# KEYSTORECTL_1.0 register map
Vendor: Texas Instruments
Peripheral module from a debugger description file (folder mspm33c321x).
Registers are 32-bit, read-write, no defined reset value unless marked. A register's access mark holds for its fields unless they carry their own. Offsets are as the file gives them; lines under a group give offsets from that group; [hi:lo] are bit positions; {n}, {i} and the like mark numbered series; 'fields as' and 'values as' point back to an identical list; <NAME> marks a mode.

## KEYSTORECTL
0x1100 KEYSTORECTL_CFG — Keystore configuration
  [3:0] NK256 — Number of 256 bit keys to be held in the key-store. Can not exceed the total number of slots present in the hardware / 2. For eg: if SYS_N_SLOTS = 4, then atmost 2 256-bit keys can be held in the key-store. Incorrect setting of this field will be reported via STATUS register
    0=ZERO (No 256-bit keys); 1=ONE (One 256-bit key); 2=TWO (Two 256-bit keys); 3=THREE (Three 256-bit keys); 4=FOUR (Four 256-bit keys)
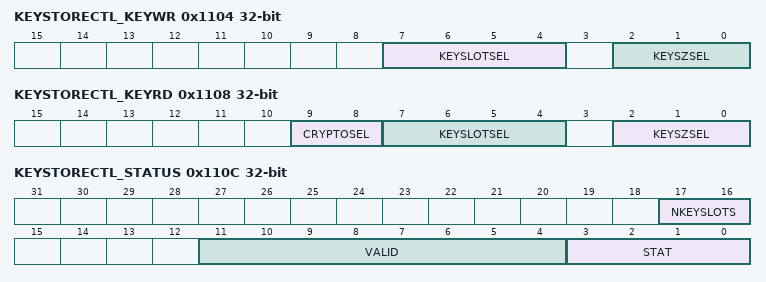
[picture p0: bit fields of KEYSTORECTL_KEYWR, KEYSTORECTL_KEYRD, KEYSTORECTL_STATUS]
0x1104 KEYSTORECTL_KEYWR — Key write configuration
  [7:4] KEYSLOTSEL — Select the key slot to write the key into. NOTE: SW needs to ensure that it is writing to the correct slots. The slot numbering is from 0 through SYS_N_SLOTS-1. Each slot is a 128-bit slot. Therefore, when writing a 256-bit key, two slots will need to budgeted. The selected slot for the 256-bit key needs to be an even numbered slot (eg: 0 or 2). Also all the 256-bit keys need to be stored in lower numbered slots and 128-bit keys stored in higher numbered slots.
    {v}=SLOT{v} (v=0..7)
  [2:0] KEYSZSEL — Key size selection. Selection of 128 or 256 bit keys
    0=K256 (256 bit key); 1=K128 (128 bit key)
0x1108 KEYSTORECTL_KEYRD — Key read configuration
  [9:8] CRYPTOSEL — Crypto engine selector
    0=AES (Transfer key to AES)
  [7:4] KEYSLOTSEL — Select the key slot to read the key from. NOTE: SW needs to ensure that it is reading from the correct slots. The slot numbering is from 0 through SYS_N_SLOTS-1. Each slot is a 128-bit slot. Therefore, when reading a 256-bit key, two adjacent slots will be read. For a 256-bit key, an even numbered slot index must be specified.
  [2:0] KEYSZSEL — Key size selection. Selection of 128 or 256 bit keys
    0=K256 (256 bit key); 1=K128 (128 bit key)
0x110C KEYSTORECTL_STATUS access per field — Status
  [17:16] NKEYSLOTS ro — Size of keystorage: Number of 128-bit key slots
    0=TWO (Two slots); 1=THREE (Three slots); 2=FOUR (Four slots)
  [11:4] VALID rw — Bitvector of valid bits to indicate which slots have been configured
  [3:0] STAT rw — Status information
    0=VALID (Valid configuration); 1=NO_CFG (Key-store has not been configured. NK256 has not been set.); 2=INVALID_NK256 (Invalid value for NK256 field in CFG.); 3=BUSY_RECEIVE (Busy receiving a key deposit); 4=BUSY_TRANSMIT (Busy transmitting a key to a crypto engine); 5=INVALID_KEYSLOTSELW (Invalid keyslot selection for writing); 6=INVALID_KEYSLOTSELR (Invalid keyslot selection for reading)
0x1110 KEYSTORECTL_KEYIN access not given — Input key
0x1114 KEYSTORECTL_KEYLOCK — Keylock
  [7:0] LOCKBIT — Bitvector of lock bits to lock certain slots from being used by application.
